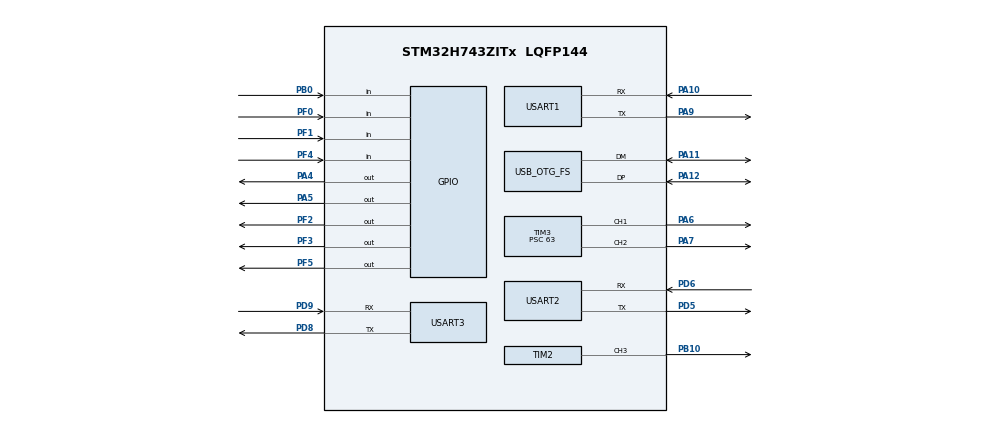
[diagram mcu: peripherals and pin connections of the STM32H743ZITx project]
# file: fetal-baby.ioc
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CORTEX_M7.default_mode_Activation=1
Mcu.Family=STM32H7
Mcu.Name=STM32H743ZITx
Mcu.Package=LQFP144
NVIC.PriorityGroup=NVIC_PRIORITYGROUP_4
NVIC.OTG_FS_IRQn=true\:7\:0\:false\:false\:true\:false\:true\:true
NVIC.USART1_IRQn=true\:6\:0\:false\:false\:true\:true\:true\:true
NVIC.USART2_IRQn=true\:5\:0\:false\:false\:true\:true\:true\:true
NVIC.USART3_IRQn=true\:5\:0\:false\:false\:true\:true\:true\:true
PA10.GPIO_Speed=GPIO_SPEED_FREQ_LOW
PA10.Mode=Asynchronous
PA10.Signal=USART1_RX
PA11.GPIO_Speed=GPIO_SPEED_FREQ_VERY_HIGH
PA11.Mode=Device_Only
PA11.Signal=USB_OTG_FS_DM
PA12.GPIO_Speed=GPIO_SPEED_FREQ_VERY_HIGH
PA12.Mode=Device_Only
PA12.Signal=USB_OTG_FS_DP
PA13\ (JTMS/SWDIO).Mode=Serial_Wire
PA13\ (JTMS/SWDIO).Signal=DEBUG_JTMS-SWDIO
PA14\ (JTCK/SWCLK).Mode=Serial_Wire
PA14\ (JTCK/SWCLK).Signal=DEBUG_JTCK-SWCLK
PA4.GPIO_Speed=GPIO_SPEED_FREQ_LOW
PA4.Signal=GPIO_Output
PA5.GPIO_Speed=GPIO_SPEED_FREQ_LOW
PA5.Signal=GPIO_Output
PA6.GPIO_Speed=GPIO_SPEED_FREQ_LOW
PA6.Signal=S_TIM3_CH1
PA7.GPIO_Speed=GPIO_SPEED_FREQ_LOW
PA7.Signal=S_TIM3_CH2
PA9.GPIO_Speed=GPIO_SPEED_FREQ_LOW
PA9.Mode=Asynchronous
PA9.Signal=USART1_TX
PB0.GPIO_PuPd=GPIO_PULLUP
PB0.Signal=GPIO_Input
PB10.GPIO_Speed=GPIO_SPEED_FREQ_LOW
PB10.Signal=S_TIM2_CH3
PF0.GPIO_PuPd=GPIO_PULLDOWN
PF0.Signal=GPIO_Input
PF1.GPIO_PuPd=GPIO_PULLDOWN
PF1.Signal=GPIO_Input
PF2.GPIO_Speed=GPIO_SPEED_FREQ_LOW
PF2.Signal=GPIO_Output
PF3.GPIO_Speed=GPIO_SPEED_FREQ_LOW
PF3.Signal=GPIO_Output
PF4.GPIO_PuPd=GPIO_PULLDOWN
PF4.Signal=GPIO_Input
PF5.GPIO_Speed=GPIO_SPEED_FREQ_LOW
PF5.Signal=GPIO_Output
PD5.GPIO_Speed=GPIO_SPEED_FREQ_LOW
PD5.Mode=Asynchronous
PD5.Signal=USART2_TX
PD6.GPIO_Speed=GPIO_SPEED_FREQ_LOW
PD6.Mode=Asynchronous
PD6.Signal=USART2_RX
PD8.GPIO_Speed=GPIO_SPEED_FREQ_LOW
PD8.Mode=Asynchronous
PD8.Signal=USART3_TX
PD9.GPIO_Speed=GPIO_SPEED_FREQ_LOW
PD9.Mode=Asynchronous
PD9.Signal=USART3_RX
ProjectManager.HeapSize=0x200
ProjectManager.StackSize=0x400
ProjectManager.TargetToolchain=STM32CubeIDE
RCC.ADCFreq_Value=129000000
RCC.APB1Freq_Value=64000000
RCC.APB2Freq_Value=64000000
RCC.APB3Freq_Value=64000000
RCC.APB4Freq_Value=64000000
RCC.CortexFreq_Value=64000000
RCC.HCLKFreq_Value=64000000
RCC.SYSCLKFreq_VALUE=64000000
RCC.USBFreq_Value=48000000
RCC.USBCLockSelection=RCC_USBCLKSOURCE_HSI48
SH.S_TIM2_CH3.0=TIM2_CH3,PWM Generation3 CH3
SH.S_TIM3_CH1.0=TIM3_CH1,PWM Generation1 CH1
SH.S_TIM3_CH2.0=TIM3_CH2,PWM Generation2 CH2
TIM2.Channel-PWM\ Generation3\ CH3=TIM_CHANNEL_3
TIM2.Period=99
TIM2.Prescaler=63
TIM3.Channel-PWM\ Generation1\ CH1=TIM_CHANNEL_1
TIM3.Channel-PWM\ Generation2\ CH2=TIM_CHANNEL_2
TIM3.Period=19999
TIM3.Prescaler=63
TIM3.Pulse-PWM\ Generation1\ CH1=1500
TIM3.Pulse-PWM\ Generation2\ CH2=1500
USART1.VirtualMode-Asynchronous=VM_ASYNC
USART2.VirtualMode-Asynchronous=VM_ASYNC
USART3.VirtualMode-Asynchronous=VM_ASYNC
USB_DEVICE.CLASS_NAME_FS=CDC
USB_DEVICE.USBD_LPM_ENABLED=0
USB_DEVICE.USBD_SELF_POWERED=0
USB_DEVICE.VirtualMode=Cdc
USB_DEVICE.VirtualModeFS=Cdc_FS
USB_OTG_FS.dev_endpoints=4
USB_OTG_FS.VirtualMode=Device_Only
USB_OTG_FS.vbus_sensing_enable=DISABLE
USB_OTG_FS.dma_enable=DISABLE
VP_MEMORYMAP_VS_MEMORYMAP.Mode=CurAppReg
VP_TIM2_VS_ClockSourceINT.Mode=Internal
VP_TIM3_VS_ClockSourceINT.Mode=Internal
VP_USB_DEVICE_VS_USB_DEVICE_CDC_FS.Mode=CDC_FS
board=custom

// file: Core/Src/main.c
/* USER CODE BEGIN Header */
/**
  ******************************************************************************
  * @file           : main.c
  * @brief          : Main program body
  ******************************************************************************
  * @attention
  *
  * Copyright (c) 2026 STMicroelectronics.
  * All rights reserved.
  *
  * This software is licensed under terms that can be found in the LICENSE file
  * in the root directory of this software component.
  * If no LICENSE file comes with this software, it is provided AS-IS.
  *
  ******************************************************************************
  */
/* USER CODE END Header */
#include "main.h"
#include "tim.h"
#include "usart.h"
#include "usb_device.h"
#include "gpio.h"

/* USER CODE BEGIN Includes */
#include "debug_uart_tx.h"
#include "baby_care_app.h"
#include "usb_observer_tx.h"

/* USER CODE END Includes */

void SystemClock_Config(void);
static void MPU_Config(void);

int main(void)
{

  /* MPU Configuration--------------------------------------------------------*/
  MPU_Config();

  /* MCU Configuration--------------------------------------------------------*/

  /* Reset of all peripherals, Initializes the Flash interface and the Systick. */
  HAL_Init();

  /* Configure the system clock */
  SystemClock_Config();

  /* USER CODE BEGIN SysInit */
  UsbObserver_Init();
  /* USER CODE END SysInit */

  /* Initialize all configured peripherals */
  MX_GPIO_Init();
  MX_TIM2_Init();
  MX_TIM3_Init();
  MX_USART1_UART_Init();
  MX_USART2_UART_Init();
  MX_USART3_UART_Init();
  MX_USB_DEVICE_Init();
  /* USER CODE BEGIN 2 */
  BabyCare_Init();

  /* USER CODE END 2 */

  /* Infinite loop */
  while (1)
  {

    /* USER CODE BEGIN 3 */
    BabyCare_Task();
    UsbObserver_Task();
  }
  /* USER CODE END 3 */
}

void SystemClock_Config(void)
{
  RCC_OscInitTypeDef RCC_OscInitStruct = {0};
  RCC_ClkInitTypeDef RCC_ClkInitStruct = {0};

  /** Supply configuration update enable
  */
  HAL_PWREx_ConfigSupply(PWR_LDO_SUPPLY);

  /** Configure the main internal regulator output voltage
  */
  __HAL_PWR_VOLTAGESCALING_CONFIG(PWR_REGULATOR_VOLTAGE_SCALE3);

  while(!__HAL_PWR_GET_FLAG(PWR_FLAG_VOSRDY)) {}

  /** Initializes the RCC Oscillators according to the specified parameters
  * in the RCC_OscInitTypeDef structure.
  */
  RCC_OscInitStruct.OscillatorType = RCC_OSCILLATORTYPE_HSI48|RCC_OSCILLATORTYPE_HSI;
  RCC_OscInitStruct.HSIState = RCC_HSI_DIV1;
  RCC_OscInitStruct.HSICalibrationValue = RCC_HSICALIBRATION_DEFAULT;
  RCC_OscInitStruct.HSI48State = RCC_HSI48_ON;
  RCC_OscInitStruct.PLL.PLLState = RCC_PLL_NONE;
  if (HAL_RCC_OscConfig(&RCC_OscInitStruct) != HAL_OK)
  {
    Error_Handler();
  }

  /** Initializes the CPU, AHB and APB buses clocks
  */
  RCC_ClkInitStruct.ClockType = RCC_CLOCKTYPE_HCLK|RCC_CLOCKTYPE_SYSCLK
                              |RCC_CLOCKTYPE_PCLK1|RCC_CLOCKTYPE_PCLK2
                              |RCC_CLOCKTYPE_D3PCLK1|RCC_CLOCKTYPE_D1PCLK1;
  RCC_ClkInitStruct.SYSCLKSource = RCC_SYSCLKSOURCE_HSI;
  RCC_ClkInitStruct.SYSCLKDivider = RCC_SYSCLK_DIV1;
  RCC_ClkInitStruct.AHBCLKDivider = RCC_HCLK_DIV1;
  RCC_ClkInitStruct.APB3CLKDivider = RCC_APB3_DIV1;
  RCC_ClkInitStruct.APB1CLKDivider = RCC_APB1_DIV1;
  RCC_ClkInitStruct.APB2CLKDivider = RCC_APB2_DIV1;
  RCC_ClkInitStruct.APB4CLKDivider = RCC_APB4_DIV1;

  if (HAL_RCC_ClockConfig(&RCC_ClkInitStruct, FLASH_LATENCY_1) != HAL_OK)
  {
    Error_Handler();
  }
}

/* USER CODE BEGIN 4 */
void HAL_UART_TxCpltCallback(UART_HandleTypeDef *huart)
{
  BabyCare_OnUartTxComplete(huart);
}

void HAL_UART_RxCpltCallback(UART_HandleTypeDef *huart)
{
  BabyCare_OnUartRxComplete(huart);
}

void HAL_UART_ErrorCallback(UART_HandleTypeDef *huart)
{
  BabyCare_OnUartError(huart);
}

/* USER CODE END 4 */

 /* MPU Configuration */

void MPU_Config(void)
{
  MPU_Region_InitTypeDef MPU_InitStruct = {0};

  /* Disables the MPU */
  HAL_MPU_Disable();

  /** Initializes and configures the Region and the memory to be protected
  */
  MPU_InitStruct.Enable = MPU_REGION_ENABLE;
  MPU_InitStruct.Number = MPU_REGION_NUMBER0;
  MPU_InitStruct.BaseAddress = 0x0;
  MPU_InitStruct.Size = MPU_REGION_SIZE_4GB;
  MPU_InitStruct.SubRegionDisable = 0x87;
  MPU_InitStruct.TypeExtField = MPU_TEX_LEVEL0;
  MPU_InitStruct.AccessPermission = MPU_REGION_NO_ACCESS;
  MPU_InitStruct.DisableExec = MPU_INSTRUCTION_ACCESS_DISABLE;
  MPU_InitStruct.IsShareable = MPU_ACCESS_SHAREABLE;
  MPU_InitStruct.IsCacheable = MPU_ACCESS_NOT_CACHEABLE;
  MPU_InitStruct.IsBufferable = MPU_ACCESS_NOT_BUFFERABLE;

  HAL_MPU_ConfigRegion(&MPU_InitStruct);
  /* Enables the MPU */
  HAL_MPU_Enable(MPU_PRIVILEGED_DEFAULT);

}

void Error_Handler(void)
{
  __disable_irq();
  while (1)
  {
  }
}
